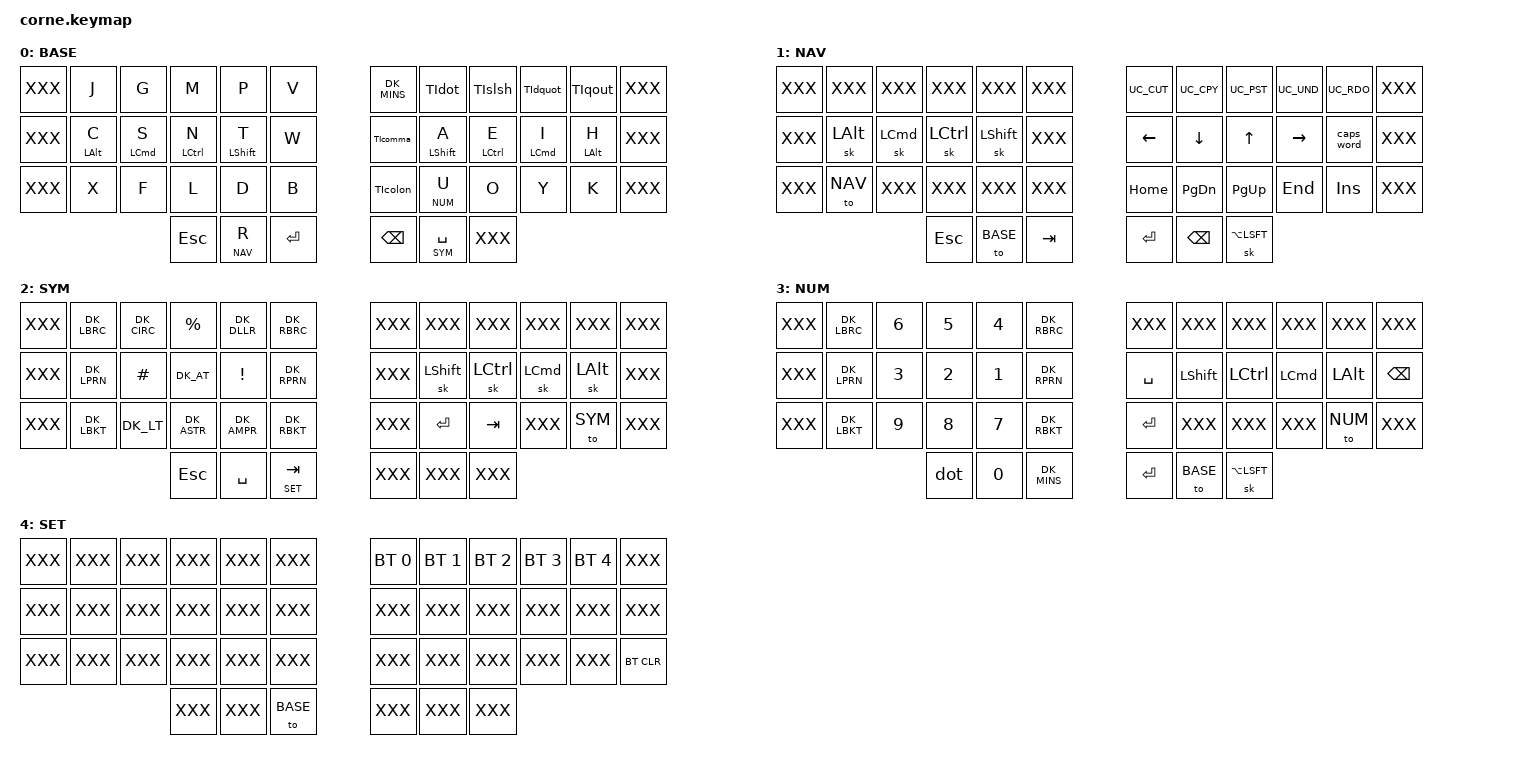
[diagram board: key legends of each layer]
#include "corne.h"

// Properties
&caps_word {
  continue-list = <UNDERSCORE SLASH MINUS BACKSPACE>;
};

&lt {
        quick-tap-ms = <QUICK_TAPPING_TERM>;
};

/ {

  macros {
	  bar_morph: bar_morph {
		  label = "bar_morph";
			compatible = "zmk,behaviors-macro";
			#binding-cells = <0>;
			bindings
			   = <&macro_release &kp LSHFT>
				 , <&macro_press &kp LALT>
				 , <&macro_tap &kp I>
				 , <&macro_release &kp LALT>
				 ;
		};
	};

  combos {
    #include "combos.dtsi"
  };

  behaviors {
		MORPH(TIcolon, &kp DK_COLN, &kp DK_SCOLN, MOD_LSFT)
		MORPH(bspc, &kp BACKSPACE, &kp DELETE, MOD_LSFT)
		MORPH(TIdot, &kp DOT, &kp DK_AMPR, MOD_LSFT)
		MORPH(TIslsh, &kp DK_SLSH, &kp DK_ASTR, MOD_LSFT)
		MORPH(TIdquot, &kp DK_DQT, &kp DK_QUES, MOD_LSFT)
		MORPH(TIqout, &kp DK_SQT, &kp EXCL, MOD_LSFT)
		MORPH(TIcomma, &kp COMMA, &kp LA(I), MOD_LSFT)
		MORPH(eql, &kp DK_EQL, &kp LG(N0), MOD_LGUI)
		MORPH(dot, &kp DOT, &kp DK_PLUS, MOD_LSFT)
		MORPH(tilde, &kp DK_TILDE, &kp DK_BSLSH, MOD_LSFT)
		lhm: left_hand_positional_hold_tap {
			compatible = "zmk,behavior-hold-tap";
			label = "LEFT_POSITIONAL_HOLD_TAP";
			#binding-cells = <2>;
			flavor = "balanced";
			tapping-term-ms = <TAPPING_TERM>;                 // <---[[produces tap if held longer than tapping-term-ms]]
			quick-tap-ms = <QUICK_TAPPING_TERM>;
			global-quick-tap;
			bindings = <&kp>, <&kp>;
			hold-trigger-key-positions = RIGHT_POSITIONS;    // <---[[right-hand keys]]
		};
		rhm: right_hand_positional_hold_tap {
			compatible = "zmk,behavior-hold-tap";
			label = "RIGHT_POSITIONAL_HOLD_TAP";
			#binding-cells = <2>;
			flavor = "balanced";
			tapping-term-ms = <TAPPING_TERM>;                 // <---[[produces tap if held longer than tapping-term-ms]]
			quick-tap-ms = <QUICK_TAPPING_TERM>;
			global-quick-tap;
			bindings = <&kp>, <&kp>;
			hold-trigger-key-positions = LEFT_POSITIONS;    // <---[[right-hand keys]]
		};
	};

  keymap {
    compatible = "zmk,keymap";

    base_layer {
      label = "BASE";
      bindings = <
        // ╭───────────┬───────────┬───────────┬───────────┬───────────┬───────────╮   ╭───────────┬───────────┬───────────┬───────────┬───────────┬───────────╮
            XXX          &kp J       &kp G       &kp M       &kp P       &kp V           &kp DK_MINS &TIdot      &TIslsh     &TIdquot    &TIqout     XXX
        // ├───────────┼───────────┼───────────┼───────────┼───────────┼───────────┤   ├───────────┼───────────┼───────────┼───────────┼───────────┼───────────┤
            XXX          &lhm LALT C &lhm LCMD S &lhm LCTRL N &lhm LSHFT T &kp W         &TIcomma  &rhm LSHFT A &rhm LCTRL E &rhm LCMD I &rhm LALT H XXX
        // ├───────────┼───────────┼───────────┼───────────┼───────────┼───────────┤   ├───────────┼───────────┼───────────┼───────────┼───────────┼───────────┤
            XXX          &kp X       &kp F       &kp L       &kp D       &kp B           &TIcolon    &lt NUM U   &kp O       &kp Y       &kp K       XXX
        // ╰───────────┴───────────┴───────────┴───────────┼───────────┼───────────┤   ├───────────┼───────────┼───────────┴───────────┴───────────┴───────────╯
                                                 &kp ESC    &lt NAV R    &kp ENTER       &kp BSPC    &lt SYM SPC XXX
        //                                     ╰───────────┴───────────┴───────────╯   ╰───────────┴───────────┴───────────╯
      >;
    };

    nav_layer {
      label = "NAV";
      bindings = <
        // ╭───────────┬───────────┬───────────┬───────────┬───────────┬───────────╮   ╭───────────┬───────────┬───────────┬───────────┬───────────┬───────────╮
             XXX         XXX         XXX         XXX         XXX         XXX             &kp UC_CUT  &kp UC_CPY  &kp UC_PST  &kp UC_UND  &kp UC_RDO  XXX
        // ├───────────┼───────────┼───────────┼───────────┼───────────┼───────────┤   ├───────────┼───────────┼───────────┼───────────┼───────────┼───────────┤
             XXX         &sk LALT    &sk LCMD    &sk LCTL    &sk LSHIFT  XXX             &kp LEFT    &kp DOWN    &kp UP      &kp RIGHT   &caps_word  XXX
        // ├───────────┼───────────┼───────────┼───────────┼───────────┼───────────┤   ├───────────┼───────────┼───────────┼───────────┼───────────┼───────────┤
             XXX         &to NAV     XXX         XXX         XXX         XXX             &kp HOME    &kp PG_DN   &kp PG_UP   &kp END     &kp INS     XXX
        // ╰───────────┴───────────┴───────────┴───────────┼───────────┼───────────┤   ├───────────┼───────────┼───────────┴───────────┴───────────┴───────────╯
                                                 &kp ESC     &to BASE    &kp TAB         &kp ENTER   &kp BSPC    &sk LA(LSFT)
        //                                     ╰───────────┴───────────┴───────────╯   ╰───────────┴───────────┴───────────╯
      >;
    };

    sym_layer {
      label = "SYM";
      bindings = <
        // ╭───────────┬───────────┬───────────┬───────────┬───────────┬───────────╮   ╭───────────┬───────────┬───────────┬───────────┬───────────┬───────────╮
             XXX        &kp DK_LBRC  &kp DK_CIRC &kp PRCNT   &kp DK_DLLR &kp DK_RBRC     XXX         XXX         XXX         XXX         XXX         XXX
        // ├───────────┼───────────┼───────────┼───────────┼───────────┼───────────┤   ├───────────┼───────────┼───────────┼───────────┼───────────┼───────────┤
             XXX        &kp DK_LPRN  &kp HASH    &kp DK_AT   &kp EXCL    &kp DK_RPRN     XXX         &sk LSHIFT  &sk LCTL    &sk LCMD    &sk LALT    XXX
        // ├───────────┼───────────┼───────────┼───────────┼───────────┼───────────┤   ├───────────┼───────────┼───────────┼───────────┼───────────┼───────────┤
             XXX        &kp DK_LBKT  &kp DK_LT   &kp DK_ASTR &kp DK_AMPR &kp DK_RBKT     XXX         &kp ENTER   &kp TAB     XXX         &to SYM     XXX
        // ╰───────────┴───────────┴───────────┼───────────┼───────────┤───────────┤   ├───────────┼───────────┼───────────┴───────────┴───────────┴───────────╯
                                                 &kp ESC     &kp SPC     &lt SET TAB     XXX         XXX         XXX
        //                                     ╰───────────┴───────────┴───────────╯   ╰───────────┴───────────┴───────────╯
      >;
    };


    num_layer {
      label = "NUM";
      bindings = <
        // ╭───────────┬───────────┬───────────┬───────────┬───────────┬───────────╮   ╭───────────┬───────────┬───────────┬───────────┬───────────┬───────────╮
             XXX         &kp DK_LBRC &kp N6      &kp N5      &kp N4      &kp DK_RBRC      XXX         XXX         XXX         XXX         XXX         XXX
        // ├───────────┼───────────┼───────────┼───────────┼───────────┼───────────┤   ├───────────┼───────────┼───────────┼───────────┼───────────┼───────────┤
             XXX         &kp DK_LPRN &kp N3      &kp N2      &kp N1      &kp DK_RPRN      &kp SPACE   &kp LSHIFT  &kp LCTL    &kp LCMD    &kp LALT    &kp BSPC
        // ├───────────┼───────────┼───────────┼───────────┼───────────┼───────────┤   ├───────────┼───────────┼───────────┼───────────┼───────────┼───────────┤
             XXX         &kp DK_LBKT &kp N9      &kp N8      &kp N7      &kp DK_RBKT      &kp ENTER   XXX         XXX         XXX         &to NUM     XXX
        // ╰───────────┴───────────┴───────────┴───────────┼───────────┼───────────┤   ├───────────┼───────────┼───────────┴───────────┴───────────┴───────────╯
                                                 &dot        &kp N0      &kp DK_MINS     &kp ENTER   &to BASE   &sk LA(LSFT)
        //                                     ╰───────────┴───────────┴───────────╯   ╰───────────┴───────────┴───────────╯
      >;
    };


    set_layer {
      label = "SET";
      bindings = <
        // ╭───────────┬───────────┬───────────┬───────────┬───────────┬───────────╮   ╭───────────┬───────────┬───────────┬───────────┬───────────┬───────────╮
             XXX         XXX         XXX         XXX         XXX         XXX           &bt BT_SEL 0 &bt BT_SEL 1 &bt BT_SEL 2 &bt BT_SEL 3 &bt BT_SEL 4 XXX
        // ├───────────┼───────────┼───────────┼───────────┼───────────┼───────────┤   ├───────────┼───────────┼───────────┼───────────┼───────────┼───────────┤
             XXX         XXX         XXX         XXX         XXX         XXX             XXX         XXX         XXX         XXX         XXX         XXX
        // ├───────────┼───────────┼───────────┼───────────┼───────────┼───────────┤   ├───────────┼───────────┼───────────┼───────────┼───────────┼───────────┤
             XXX         XXX         XXX         XXX         XXX         XXX             XXX         XXX         XXX         XXX         XXX         &bt BT_CLR
        // ╰───────────┴───────────┴───────────┼───────────┼───────────┤───────────┤   ├───────────┼───────────┼───────────┴───────────┴───────────┴───────────╯
                                                 XXX         XXX         &to BASE        XXX         XXX         XXX
        //                                     ╰───────────┴───────────┴───────────╯   ╰───────────┴───────────┴───────────╯
      >;
    };

  };
};
